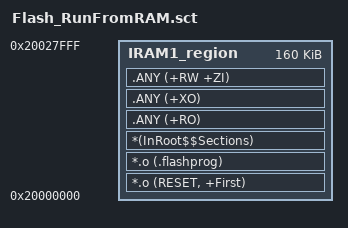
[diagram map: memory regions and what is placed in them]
#! armclang -E --target=arm-arm-none-eabi -mcpu=cortex-m4 -x c


; *************************************************************
; *** Scatter-Loading Description File generated by uVision ***
; *************************************************************


; ###ICF### Section handled by ICF editor, don't touch! ****/
; -Editor annotation file-*/
; /* IcfEditorFile="$TOOLKIT_DIR$\config\ide\IcfEditor\cortex_v1_1.xml" */
; /*-Specials-*/
;#define intvec_start__ 0x20000000

; /*-Memory Regions-*/
#define ROM_start      0x00000000
#define ROM_size       0x00020000
#define FLASH_start__  0x10000000
#define FLASH_size__   0x00100000
#define SPIX_start__   0x08000000
#define SPIX_size__    0x05A12000
#define IRAM_start__   0x20000000
#define IRAM_size__    0x00028000


; /*-Sizes */
;#define size_cstack__  0x6000
;#define size_heap__    0x2000
; /**** End of ICF editor section. ###ICF###*/

#define memory mem with size = 4G;


LR_IROM1 IRAM_start__ IRAM_size__  {    ; load region size_region

  IRAM1_region IRAM_start__  IRAM_size__ {
   *.o (RESET, +First)  
   *.o (.flashprog)
   *(InRoot$$Sections)
   .ANY (+RO)
   .ANY (+XO)
   .ANY (+RW +ZI)
  }
  
}
